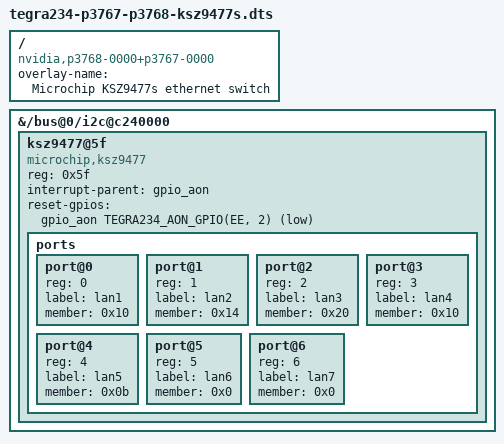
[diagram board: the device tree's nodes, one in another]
// SPDX-License-Identifier: GPL-2.0-only
// SPDX-FileCopyrightText: Copyright (c) 2023-2024, SSRC/TII. All rights reserved.

/dts-v1/;
/plugin/;

#include <dt-bindings/clock/tegra234-clock.h>
#include <dt-bindings/gpio/tegra234-gpio.h>

/ {
    overlay-name = "Microchip KSZ9477s ethernet switch";
    compatible = "nvidia,p3768-0000+p3767-0000";


    fragment@0 {
        target-path = "/bus@0/i2c@c240000";
        __overlay__ {
                ksz9477@5f {
                    compatible = "microchip,ksz9477";
                    reg = <0x5f>;
                    status = "okay";
                    interrupt-parent = <&gpio_aon>;
                    reset-gpios = <&gpio_aon TEGRA234_AON_GPIO(EE, 2) GPIO_ACTIVE_LOW>;

                    ports {
                        #address-cells = <1>;
                        #size-cells = <0>;

                        port@0 {
                            reg = <0>;
                            label = "lan1";
                            member = <0x10>;
                        };

                        port@1 {
                            reg = <1>;
                            label = "lan2";
                            member = <0x14>;
                        };

                        port@2 {
                            reg = <2>;
                            label = "lan3";
                            member = <0x20>;
                        };

                        port@3 {
                            reg = <3>;
                            label = "lan4";
                            member = <0x10>;
                        };

                        port@4 {
                            reg = <4>;
                            label = "lan5";
                            member = <0x0b>;
                        };

                        port@5 {
                            reg = <5>;
                            label = "lan6";
                            member = <0x0>;
                        };

                        port@6 {
                            reg = <6>;
                            label = "lan7";
                            member = <0x0>;
                        };
                    };
                };
        };
    };
};
